# STM32H743 register map
File version: 2.4
CPU: CM7 r0p1, little endian, MPU, FPU, 4 interrupt priority bits
Registers are 32-bit, read-write, reset 0x0 unless marked. A register's access mark holds for its fields unless they carry their own. Offsets are from the block's base; [hi:lo] are bit positions.

## COMP1 — 比较器 1
Base 0x58003800
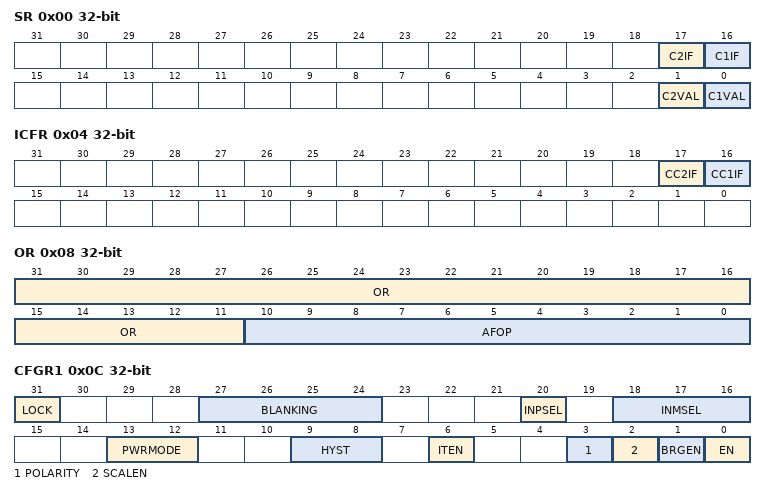
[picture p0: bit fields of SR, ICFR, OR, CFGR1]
0x00 SR ro — 比较器状态寄存器
  [17] C2IF — 比较器通道 2 中断标志
  [16] C1IF — 比较器通道 1 中断标志
  [1] C2VAL — 比较器通道 2 输出状态位
  [0] C1VAL — 比较器通道 1 输出状态位
0x04 ICFR wo — 比较器中断标志清除寄存器
  [17] CC2IF — 清除比较器通道 2 中断标志
  [16] CC1IF — 清除比较器通道 1 中断标志
0x08 OR — 比较器选项寄存器
  [31:11] OR — 选项寄存器
  [10:0] AFOP — 输出端口复用功能源选择
0x0C CFGR1 — 比较器配置寄存器 1
  [31] LOCK — 锁定位
  [27:24] BLANKING — 比较器通道 1 消隐源选择位
  [20] INPSEL — 比较器通道 1 同相输入选择位
  [18:16] INMSEL — 比较器通道 1 反相输入选择
  [13:12] PWRMODE — 比较器通道 1 功耗模式
  [9:8] HYST — 比较器通道 1 迟滞选择位
  [6] ITEN — 比较器通道 1 中断使能
  [3] POLARITY — 比较器通道 1 极性选择位
  [2] SCALEN — 电压分压器使能位
  [1] BRGEN — 分压桥使能
  [0] EN — 比较器通道 1 使能位
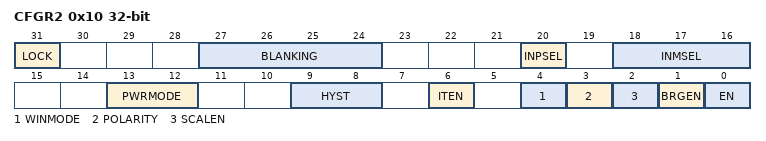
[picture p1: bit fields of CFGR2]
0x10 CFGR2 — 比较器配置寄存器 2
  [31] LOCK — 锁定位
  [27:24] BLANKING — 比较器通道 1 消隐源选择位
  [20] INPSEL — 比较器通道 1 同相输入选择位
  [18:16] INMSEL — 比较器通道 1 反相输入选择
  [13:12] PWRMODE — 比较器通道 1 功耗模式
  [9:8] HYST — 比较器通道 1 迟滞选择位
  [6] ITEN — 比较器通道 1 中断使能
  [4] WINMODE — 窗口比较器模式选择位
  [3] POLARITY — 比较器通道 1 极性选择位
  [2] SCALEN — 电压分压器使能位
  [1] BRGEN — 分压桥使能
  [0] EN — 比较器通道 1 使能位

## CRS
Base 0x40008400
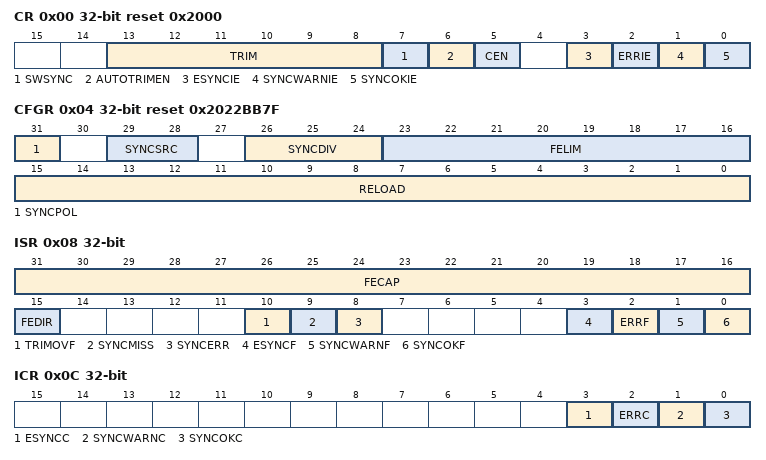
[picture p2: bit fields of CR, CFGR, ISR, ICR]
0x00 CR access per field reset 0x2000 — CRS 控制寄存器
  [13:8] TRIM rw — HSI48 振荡器平滑微调 这些位为 HSI48 振荡器提供用户可编程的微调值。可对其进行编程，以补偿电压和温度变化对 HSI48 频率的影响。默认值为 32，对应微调区间的中间位置。相邻两个 TRIM 步进对应的微调步长约为 67 kHz。TRIM 值越大，输出频率越高。当 AUTOTRIMEN 位置 1 时，此字段由硬件控制且为只读。
  [7] SWSYNC ro — 生成软件 SYNC 事件 此位由软件置 1，用于生成一次软件 SYNC 事件。由硬件自动清零。
  [6] AUTOTRIMEN rw — 自动微调使能 该位使能根据两次 SYNC 事件之间测得的频率误差对 TRIM 位进行自动硬件调整。若此位置 1，TRIM 位为只读。硬件可根据测得的频率误差值，每次对 TRIM 值调整一步或两步。详见第 7.3.4 节：频率误差评估与自动微调。
  [5] CEN rw — 频率误差计数器使能 该位使能频率误差计数器的振荡器时钟。当此位置 1 时，CRS_CFGR 寄存器将被写保护，不可修改。
  [3] ESYNCIE rw — 预期 SYNC 中断使能
  [2] ERRIE rw — 同步或微调错误中断使能
  [1] SYNCWARNIE rw — SYNC 警告中断使能
  [0] SYNCOKIE rw — SYNC 事件成功中断使能
0x04 CFGR reset 0x2022BB7F — 此寄存器仅可在频率误差计数器禁用（CRS_CR 寄存器中 CEN 位清零）时写入。计数器使能后，此寄存器将被写保护。
  [31] SYNCPOL — SYNC 极性选择 此位由软件置 1 或清零，用于选择 SYNC 信号源的输入极性。
  [29:28] SYNCSRC — SYNC 信号源选择 这些位由软件置 1 或清零，用于选择 SYNC 信号源。注意：使用 USB LPM（链路电源管理）且设备处于睡眠模式时，主机将不会产生周期性的 USB SOF。因此，CRS 将无法获得 SYNC 信号来在运行中校准 HSI48。为保证从睡眠模式唤醒后所需的时钟精度，应使用 LSE 或 GPIO 上的参考时钟作为 SYNC 信号。
  [26:24] SYNCDIV — SYNC 分频器 这些位由软件置 1 或清零，用于控制 SYNC 信号的分频因子。
  [23:16] FELIM — 频率误差限值 FELIM 包含用于评估 CRS_ISR 寄存器 FECAP[15:0] 位中锁存的频率误差捕获值的值。有关 FECAP 评估的详细信息，请参见第 7.3.4 节：频率误差评估与自动微调。
  [15:0] RELOAD — 计数器重载值 RELOAD 为每次 SYNC 事件时加载到频率误差计数器中的值。有关计数器行为的详细信息，请参见第 7.3.3 节：频率误差测量。
0x08 ISR ro — CRS 中断和状态寄存器
  [31:16] FECAP — 频率误差捕获 FECAP 为上次 SYNC 事件时锁存的频率误差计数器值。有关 FECAP 使用的详细信息，请参见第 7.3.4 节：频率误差评估与自动微调。
  [15] FEDIR — 频率误差方向 FEDIR 为上次 SYNC 事件时锁存的频率误差计数器计数方向。它指示实际频率是低于还是高于目标值。
  [10] TRIMOVF — 微调上溢或下溢 当自动微调尝试使 TRIM 值上溢或下溢时，硬件将此标志置 1。若 CRS_CR 寄存器中 ERRIE 位置 1，则会产生中断。通过将 CRS_ICR 寄存器中 ERRC 位置 1，由软件清除此标志。
  [9] SYNCMISS — SYNC 丢失 当频率误差计数器达到 FELIM × 128 且未检测到 SYNC 时，硬件将此标志置 1，这意味着丢失了一个 SYNC 脉冲，或频率误差过大（内部频率过高），无法通过调整 TRIM 值来补偿，需采取其他措施。此时，频率误差计数器停止（等待下一次 SYNC），若 CRS_CR 寄存器中 ERRIE 位置 1，则会产生中断。通过将 CRS_ICR 寄存器中 ERRC 位置 1，由软件清除此标志。
  [8] SYNCERR — SYNC 误差 当 SYNC 脉冲在 ESYNC 事件之前到达且测得的频率误差大于或等于 FELIM × 128 时，硬件将此标志置 1。这意味着频率误差过大（内部频率过低），无法通过调整 TRIM 值来补偿，需采取其他措施。若 CRS_CR 寄存器中 ERRIE 位置 1，则会产生中断。通过将 CRS_ICR 寄存器中 ERRC 位置 1，由软件清除此标志。
  [3] ESYNCF — 预期 SYNC 标志 当频率误差计数器达到零值时，硬件将此标志置 1。若 CRS_CR 寄存器中 ESYNCIE 位置 1，则会产生中断。通过将 CRS_ICR 寄存器中 ESYNCC 位置 1，由软件清除此标志。
  [2] ERRF — 错误标志 当发生任何同步或微调错误时，硬件将此标志置 1。它是 TRIMOVF、SYNCMISS 和 SYNCERR 位的逻辑或。若 CRS_CR 寄存器中 ERRIE 位置 1，则会产生中断。软件通过将 CRS_ICR 寄存器中 ERRC 位置 1 来清除此标志，该操作同时清除 TRIMOVF、SYNCMISS 和 SYNCERR 位。
  [1] SYNCWARNF — SYNC 警告标志 当测得的频率误差大于或等于 FELIM × 3 但小于 FELIM × 128 时，硬件将此标志置 1。这意味着为补偿频率误差，需将 TRIM 值调整两个步长或更多。若 CRS_CR 寄存器中 SYNCWARNIE 位置 1，则会产生中断。通过将 CRS_ICR 寄存器中 SYNCWARNC 位置 1，由软件清除此标志。
  [0] SYNCOKF — SYNC 事件成功标志 当测得的频率误差小于 FELIM × 3 时，硬件将此标志置 1。这意味着无需调整 TRIM 值，或只需调整一个微调步长即可补偿频率误差。若 CRS_CR 寄存器中 SYNCOKIE 位置 1，则会产生中断。通过将 CRS_ICR 寄存器中 SYNCOKC 位置 1，由软件清除此标志。
0x0C ICR — CRS 中断标志清除寄存器
  [3] ESYNCC — 预期 SYNC 清除标志 向此位写 1 可清除 CRS_ISR 寄存器中的 ESYNCF 标志。
  [2] ERRC — 错误清除标志 向此位写 1 可清除 TRIMOVF、SYNCMISS 和 SYNCERR 位，从而同时清除 CRS_ISR 寄存器中的 ERRF 标志。
  [1] SYNCWARNC — SYNC 警告清除标志 向此位写 1 可清除 CRS_ISR 寄存器中的 SYNCWARNF 标志。
  [0] SYNCOKC — SYNC 事件成功清除标志 向此位写 1 可清除 CRS_ISR 寄存器中的 SYNCOKF 标志。
